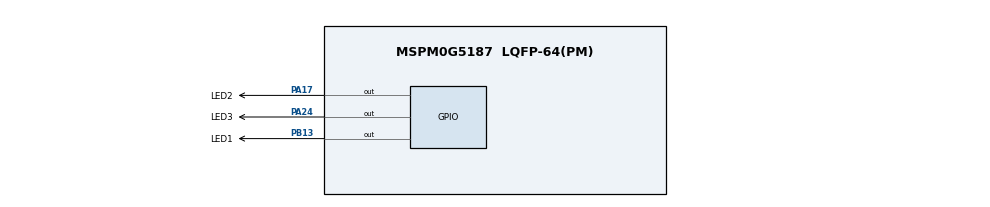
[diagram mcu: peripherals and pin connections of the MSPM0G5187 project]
//@cliArgs --device "MSPM0G518X" --package "LQFP-64(PM)" --part "Default"
//@v2CliArgs --device "MSPM0G5187" --package "LQFP-64(PM)"
// @cliArgs --board /ti/boards/LP_MSPM0G5187 --rtos nortos

/**
 * Import the modules used in this configuration.
 */
const GPIO          = scripting.addModule("/ti/driverlib/GPIO", {}, false);
const GPIO1         = GPIO.addInstance();
const SYSCTL        = scripting.addModule("/ti/driverlib/SYSCTL");
const ProjectConfig = scripting.addModule("/ti/project_config/ProjectConfig");

/**
 * Write custom configuration values to the imported modules.
 */
GPIO1.$name                         = "GPIO_LEDS";
GPIO1.associatedPins.create(3);
GPIO1.associatedPins[0].$name       = "LED1";
GPIO1.associatedPins[0].pin.$assign = "PB13";
GPIO1.associatedPins[1].$name       = "LED2";
GPIO1.associatedPins[1].pin.$assign = "PA17";
GPIO1.associatedPins[2].$name       = "LED3";
GPIO1.associatedPins[2].pin.$assign = "PA24";

const Board = scripting.addModule("/ti/driverlib/Board", {}, false);

SYSCTL.validateClkStatus = true;
SYSCTL.MCLKSource        = "HSCLK";
SYSCTL.SYSPLL_CLK0En     = true;

ProjectConfig.genLibNPU   = true;
ProjectConfig.genLibCMSIS = true;
